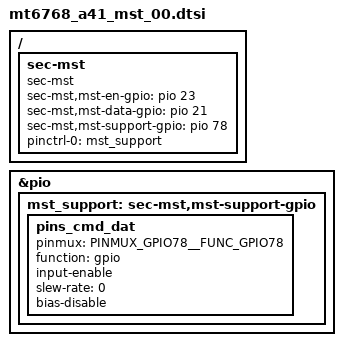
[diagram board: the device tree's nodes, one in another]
/* Copyright (c) 2019, Samsung Electronics Corporation. All rights reserved.
 *
 * This program is free software; you can redistribute it and/or modify
 * it under the terms of the GNU General Public License version 2 and
 * only version 2 as published by the Free Software Foundation.
 *
 * This program is distributed in the hope that it will be useful,
 * but WITHOUT ANY WARRANTY; without even the implied warranty of
 * MERCHANTABILITY or FITNESS FOR A PARTICULAR PURPOSE.  See the
 * GNU General Public License for more details.
 */

/ {
	fragment@model {
		target-path = "/";
		__overlay__ {
			sec-mst{
				compatible = "sec-mst";
				//sec-mst,mst-pwr-gpio = <&gpm18 0 0>;
				sec-mst,mst-en-gpio = <&pio 23 0>;
				sec-mst,mst-data-gpio = <&pio 21 0>;
				sec-mst,mst-support-gpio = <&pio 78 0>; 

				pinctrl-names = "default";
				pinctrl-0 = <&mst_support>;
			};
		};
	};
};

&pio {
	mst_support: sec-mst,mst-support-gpio {
		pins_cmd_dat {
			pinmux = <PINMUX_GPIO78__FUNC_GPIO78>;
			function = "gpio";
			input-enable;
			slew-rate = <0>;
			bias-disable;
		};
	};
};
